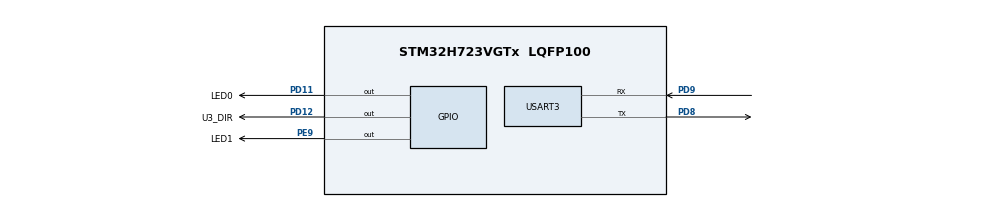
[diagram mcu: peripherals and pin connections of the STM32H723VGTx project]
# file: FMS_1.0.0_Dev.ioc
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CORTEX_M7.default_mode_Activation=1
Dma.Request0=USART3_RX
Dma.USART3_RX.0.Direction=DMA_PERIPH_TO_MEMORY
Dma.USART3_RX.0.EventEnable=DISABLE
Dma.USART3_RX.0.FIFOMode=DMA_FIFOMODE_DISABLE
Dma.USART3_RX.0.Instance=DMA1_Stream0
Dma.USART3_RX.0.MemDataAlignment=DMA_MDATAALIGN_BYTE
Dma.USART3_RX.0.MemInc=DMA_MINC_ENABLE
Dma.USART3_RX.0.Mode=DMA_CIRCULAR
Dma.USART3_RX.0.PeriphDataAlignment=DMA_PDATAALIGN_BYTE
Dma.USART3_RX.0.PeriphInc=DMA_PINC_DISABLE
Dma.USART3_RX.0.Polarity=HAL_DMAMUX_REQ_GEN_RISING
Dma.USART3_RX.0.Priority=DMA_PRIORITY_MEDIUM
Dma.USART3_RX.0.RequestNumber=1
Dma.USART3_RX.0.SignalID=NONE
Dma.USART3_RX.0.SyncEnable=DISABLE
Dma.USART3_RX.0.SyncPolarity=HAL_DMAMUX_SYNC_NO_EVENT
Dma.USART3_RX.0.SyncRequestNumber=1
Dma.USART3_RX.0.SyncSignalID=NONE
Mcu.Family=STM32H7
Mcu.Name=STM32H723VGTx
Mcu.Package=LQFP100
NVIC.DMA1_Stream0_IRQn=true\:5\:0\:true\:false\:true\:false\:true\:true
NVIC.PriorityGroup=NVIC_PRIORITYGROUP_4
NVIC.USART3_IRQn=true\:5\:0\:true\:false\:true\:true\:true\:true
PA13(JTMS/SWDIO).Mode=Serial_Wire
PA13(JTMS/SWDIO).Signal=DEBUG_JTMS-SWDIO
PA14(JTCK/SWCLK).Mode=Serial_Wire
PA14(JTCK/SWCLK).Signal=DEBUG_JTCK-SWCLK
PD11.GPIO_Label=LED0
PD11.PinState=GPIO_PIN_SET
PD11.Signal=GPIO_Output
PD12.GPIO_Label=U3_DIR
PD12.GPIO_Speed=GPIO_SPEED_FREQ_MEDIUM
PD12.Signal=GPIO_Output
PD8.Mode=Asynchronous
PD8.Signal=USART3_TX
PD9.Mode=Asynchronous
PD9.Signal=USART3_RX
PE9.GPIO_Label=LED1
PE9.PinState=GPIO_PIN_SET
PE9.Signal=GPIO_Output
PH0-OSC_IN.Mode=HSE-External-Oscillator
PH0-OSC_IN.Signal=RCC_OSC_IN
PH1-OSC_OUT.Mode=HSE-External-Oscillator
PH1-OSC_OUT.Signal=RCC_OSC_OUT
ProjectManager.HeapSize=0x200
ProjectManager.StackSize=0x400
ProjectManager.TargetToolchain=MDK-ARM V5.32
RCC.ADCFreq_Value=16125000
RCC.APB1Freq_Value=100000000
RCC.APB2Freq_Value=100000000
RCC.APB3Freq_Value=100000000
RCC.APB4Freq_Value=100000000
RCC.CortexFreq_Value=400000000
RCC.D1PPRE=RCC_APB3_DIV2
RCC.D2PPRE1=RCC_APB1_DIV2
RCC.D2PPRE2=RCC_APB2_DIV2
RCC.D3PPRE=RCC_APB4_DIV2
RCC.DIVM1=1
RCC.DIVN1=50
RCC.DIVP1=1
RCC.HCLKFreq_Value=200000000
RCC.HPRE=RCC_HCLK_DIV2
RCC.HSE_VALUE=8000000
RCC.PLL2FRACN=0
RCC.PLL3FRACN=0
RCC.PLLFRACN=0
RCC.PLLSourceVirtual=RCC_PLLSOURCE_HSE
RCC.SYSCLKFreq_VALUE=400000000
RCC.SYSCLKSource=RCC_SYSCLKSOURCE_PLLCLK
RCC.USBFreq_Value=200000000
TIM5.Prescaler=199
USART3.VirtualMode-Asynchronous=VM_ASYNC
VP_MEMORYMAP_VS_MEMORYMAP.Mode=CurAppReg
VP_TIM5_VS_ClockSourceINT.Mode=Internal
board=custom

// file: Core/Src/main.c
/* USER CODE BEGIN Header */
/**
  ******************************************************************************
  * @file           : main.c
  * @brief          : Main program body
  ******************************************************************************
  * @attention
  *
  * Copyright (c) 2026 STMicroelectronics.
  * All rights reserved.
  *
  * This software is licensed under terms that can be found in the LICENSE file
  * in the root directory of this software component.
  * If no LICENSE file comes with this software, it is provided AS-IS.
  *
  ******************************************************************************
  */
/* USER CODE END Header */
#include "main.h"
#include "dma.h"
#include "tim.h"
#include "usart.h"
#include "gpio.h"

/* USER CODE BEGIN Includes */
#include "app_main.h"
#include "svc_sched.h"
#include "svc_tim.h"
#include <string.h>
//#include "svc_rs485.h"
/* USER CODE END Includes */

void SystemClock_Config(void);
static void MPU_Config(void);

int main(void)
{

  /* MPU Configuration--------------------------------------------------------*/
  MPU_Config();

  /* MCU Configuration--------------------------------------------------------*/

  /* Reset of all peripherals, Initializes the Flash interface and the Systick. */
  HAL_Init();

  /* Configure the system clock */
  SystemClock_Config();

  /* USER CODE BEGIN SysInit */
//SCB_DisableDCache();
//SCB_DisableICache(); // 锟斤拷选
  /* USER CODE END SysInit */

  /* Initialize all configured peripherals */
  MX_GPIO_Init();
  MX_DMA_Init();
  MX_TIM5_Init();
  MX_USART3_UART_Init();
  /* USER CODE BEGIN 2 */
//	uart_rx_init();
//	LL_GPIO_SetOutputPin(U3_DIR_GPIO_Port, U3_DIR_Pin);  // 锟斤拷锟斤拷为锟斤拷锟斤拷模式
//    LL_mDelay(1);
//    while(!LL_USART_IsActiveFlag_TXE(USART3));
//    LL_USART_TransmitData8(USART3, 'A');  // 锟斤拷锟酵诧拷锟斤拷锟街凤拷
//    while(!LL_USART_IsActiveFlag_TC(USART3));
//    LL_GPIO_ResetOutputPin(U3_DIR_GPIO_Port, U3_DIR_Pin);  // 锟斤拷锟斤拷为锟斤拷锟斤拷模式

//  /* USER CODE END 2 */

//  /* Infinite loop */
//  /* USER CODE BEGIN WHILE */

//uint8_t tmp[256];
  while (1)
  {
    /* USER CODE END WHILE */

    /* USER CODE BEGIN 3 */
	  LL_GPIO_TogglePin(LED0_GPIO_Port, LED0_Pin);
    LL_mDelay(1000); // 延时500ms，确保肉眼可见
//    static uint32_t last_send = 0;
//    if(HAL_GetTick() - last_send > 2000)
//    {
//        const uint8_t test_data[] = "TEST\r\n"; // 发送固定的6个字节
//
//        // 1. 置位DE引脚，进入发送模式
//        LL_GPIO_SetOutputPin(GPIOD, LL_GPIO_PIN_12); // 确保这是你的DE引脚
//        LL_mDelay(1); // 给RS485芯片一个稳定时间
//
//        // 2. 轮询发送每一个字节
//        for(int i = 0; i < sizeof(test_data)-1; i++) // -1 是为了不发送字符串结尾的\0
//        {
//            // 等待发送寄存器空
//            while(!LL_USART_IsActiveFlag_TXE(USART3));
//            // 写入数据，开始发送
//            LL_USART_TransmitData8(USART3, test_data[i]);
//        }
//
//        // 3. 等待最后一个字节的发送完成
//        while(!LL_USART_IsActiveFlag_TC(USART3));
//
//        // 4. 复位DE引脚，返回接收模式
//        LL_GPIO_ResetOutputPin(GPIOD, LL_GPIO_PIN_12);
//
//        // 5. 用LED指示一次发送完成
//        LL_GPIO_TogglePin(LED0_GPIO_Port, LED0_Pin);
//
//        last_send = HAL_GetTick();
//    }
//
//    // 测试2：简单的轮询接收（如果自发自收）
//    if(LL_USART_IsActiveFlag_RXNE(USART3))
//    {
//        uint8_t ch = LL_USART_ReceiveData8(USART3);
//        // 如果收到任何数据，快速闪烁另一个LED（比如LED1）指示
//        // LL_GPIO_TogglePin(LED1_GPIO_Port, LED1_Pin);
//    }
//
//    LL_mDelay(10);
}
//        uint32_t n = uart_rx_read(tmp, sizeof(tmp));
//        if (n > 0) {
////            LL_GPIO_SetOutputPin(LED0_GPIO_Port, LED0_Pin);
//			LL_GPIO_SetOutputPin(U3_DIR_GPIO_Port, U3_DIR_Pin);
//            LL_mDelay(1);
//
//
//            for(int i = 0; i < n; i++) {
//                while(!LL_USART_IsActiveFlag_TXE(USART3));
//                LL_USART_TransmitData8(USART3, tmp[i]);
//            }
//            while(!LL_USART_IsActiveFlag_TC(USART3));
//            LL_GPIO_ResetOutputPin(U3_DIR_GPIO_Port, U3_DIR_Pin);
//
//            LL_GPIO_ResetOutputPin(LED0_GPIO_Port, LED0_Pin);
//        }
//
//        LL_mDelay(5);
//        if(LL_USART_IsActiveFlag_ORE(USART3) ||
//           LL_USART_IsActiveFlag_FE(USART3) ||
//           LL_USART_IsActiveFlag_NE(USART3))
//		{
//            LL_USART_ClearFlag_ORE(USART3);
//            LL_USART_ClearFlag_FE(USART3);
//            LL_USART_ClearFlag_NE(USART3);
//        }
////LL_GPIO_TogglePin(LED0_GPIO_Port,LED0_Pin);
////			LL_mDelay(100);
//	}
  /* USER CODE END 3 */
}

void SystemClock_Config(void)
{
  LL_FLASH_SetLatency(LL_FLASH_LATENCY_2);
  while(LL_FLASH_GetLatency()!= LL_FLASH_LATENCY_2)
  {
  }
  LL_PWR_ConfigSupply(LL_PWR_LDO_SUPPLY);
  LL_PWR_SetRegulVoltageScaling(LL_PWR_REGU_VOLTAGE_SCALE1);
  while (LL_PWR_IsActiveFlag_VOS() == 0)
  {
  }
  LL_RCC_HSE_Enable();

   /* Wait till HSE is ready */
  while(LL_RCC_HSE_IsReady() != 1)
  {

  }
  LL_RCC_PLL_SetSource(LL_RCC_PLLSOURCE_HSE);
  LL_RCC_PLL1P_Enable();
  LL_RCC_PLL1R_Enable();
  LL_RCC_PLL1_SetVCOInputRange(LL_RCC_PLLINPUTRANGE_8_16);
  LL_RCC_PLL1_SetVCOOutputRange(LL_RCC_PLLVCORANGE_WIDE);
  LL_RCC_PLL1_SetM(1);
  LL_RCC_PLL1_SetN(50);
  LL_RCC_PLL1_SetP(1);
  LL_RCC_PLL1_SetQ(2);
  LL_RCC_PLL1_SetR(2);
  LL_RCC_PLL1_Enable();

   /* Wait till PLL is ready */
  while(LL_RCC_PLL1_IsReady() != 1)
  {
  }

   /* Intermediate AHB prescaler 2 when target frequency clock is higher than 80 MHz */
   LL_RCC_SetAHBPrescaler(LL_RCC_AHB_DIV_2);

  LL_RCC_SetSysClkSource(LL_RCC_SYS_CLKSOURCE_PLL1);

   /* Wait till System clock is ready */
  while(LL_RCC_GetSysClkSource() != LL_RCC_SYS_CLKSOURCE_STATUS_PLL1)
  {

  }
  LL_RCC_SetSysPrescaler(LL_RCC_SYSCLK_DIV_1);
  LL_RCC_SetAHBPrescaler(LL_RCC_AHB_DIV_2);
  LL_RCC_SetAPB1Prescaler(LL_RCC_APB1_DIV_2);
  LL_RCC_SetAPB2Prescaler(LL_RCC_APB2_DIV_2);
  LL_RCC_SetAPB3Prescaler(LL_RCC_APB3_DIV_2);
  LL_RCC_SetAPB4Prescaler(LL_RCC_APB4_DIV_2);
  LL_SetSystemCoreClock(400000000);

   /* Update the time base */
  if (HAL_InitTick (TICK_INT_PRIORITY) != HAL_OK)
  {
    Error_Handler();
  }
}

 /* MPU Configuration */

void MPU_Config(void)
{

  /* Disables the MPU */
  LL_MPU_Disable();

  /** Initializes and configures the Region and the memory to be protected
  */
  LL_MPU_ConfigRegion(LL_MPU_REGION_NUMBER0, 0x87, 0x0, LL_MPU_REGION_SIZE_4GB|LL_MPU_TEX_LEVEL0|LL_MPU_REGION_NO_ACCESS|LL_MPU_INSTRUCTION_ACCESS_DISABLE|LL_MPU_ACCESS_SHAREABLE|LL_MPU_ACCESS_NOT_CACHEABLE|LL_MPU_ACCESS_NOT_BUFFERABLE);
  /* Enables the MPU */
  LL_MPU_Enable(LL_MPU_CTRL_PRIVILEGED_DEFAULT);

}

void Error_Handler(void)
{
  __disable_irq();
  while (1)
  {
  }
}
